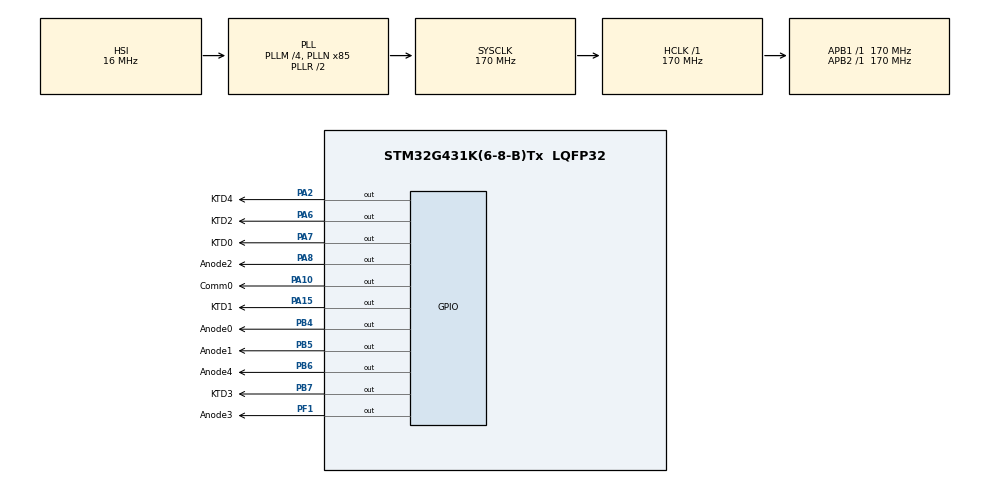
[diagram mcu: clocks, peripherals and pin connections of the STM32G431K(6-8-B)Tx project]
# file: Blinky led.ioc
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Mcu.Family=STM32G4
Mcu.Name=STM32G431K(6-8-B)Tx
Mcu.Package=LQFP32
NVIC.PriorityGroup=NVIC_PRIORITYGROUP_4
PA10.GPIO_Label=Comm0
PA10.Signal=GPIO_Output
PA13.GPIO_Label=T_SWDIO
PA13.Mode=Serial_Wire
PA13.Signal=SYS_JTMS-SWDIO
PA14.GPIO_Label=T_SWCLK
PA14.Mode=Serial_Wire
PA14.Signal=SYS_JTCK-SWCLK
PA15.GPIO_Label=KTD1
PA15.Signal=GPIO_Output
PA2.GPIO_Label=KTD4
PA2.Signal=GPIO_Output
PA6.GPIO_Label=KTD2
PA6.Signal=GPIO_Output
PA7.GPIO_Label=KTD0
PA7.PinState=GPIO_PIN_RESET
PA7.Signal=GPIO_Output
PA8.GPIO_Label=Anode2
PA8.Signal=GPIO_Output
PB3.GPIO_Label=T_SWO
PB3.Signal=SYS_JTDO-SWO
PB4.GPIO_Label=Anode0
PB4.PinState=GPIO_PIN_RESET
PB4.Signal=GPIO_Output
PB5.GPIO_Label=Anode1
PB5.Signal=GPIO_Output
PB6.GPIO_Label=Anode4
PB6.Signal=GPIO_Output
PB7.GPIO_Label=KTD3
PB7.Signal=GPIO_Output
PF1-OSC_OUT.GPIO_Label=Anode3
PF1-OSC_OUT.Signal=GPIO_Output
ProjectManager.HeapSize=0x200
ProjectManager.StackSize=0x400
ProjectManager.TargetToolchain=STM32CubeIDE
RCC.ADC12Freq_Value=170000000
RCC.AHBFreq_Value=170000000
RCC.APB1Freq_Value=170000000
RCC.APB1TimFreq_Value=170000000
RCC.APB2Freq_Value=170000000
RCC.APB2TimFreq_Value=170000000
RCC.CortexFreq_Value=170000000
RCC.EXTERNAL_CLOCK_VALUE=12288000
RCC.HCLKFreq_Value=170000000
RCC.HSE_VALUE=8000000
RCC.HSI48_VALUE=48000000
RCC.HSI_VALUE=16000000
RCC.LSE_VALUE=32768
RCC.PLLM=RCC_PLLM_DIV4
RCC.PLLN=85
RCC.SYSCLKFreq_VALUE=170000000
RCC.SYSCLKSource=RCC_SYSCLKSOURCE_PLLCLK
RCC.USBFreq_Value=170000000
RCC.VCOOutputFreq_Value=340000000
VP_SYS_VS_DBSignals.Mode=DisableDeadBatterySignals
board=NUCLEO-G431KB

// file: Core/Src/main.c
/* USER CODE BEGIN Header */
/**
  ******************************************************************************
  * @file           : main.c
  * @brief          : Main program body
  ******************************************************************************
  * @attention
  *
  * <h2><center>&copy; Copyright (c) 2021 STMicroelectronics.
  * All rights reserved.</center></h2>
  *
  * This software component is licensed by ST under BSD 3-Clause license,
  * the "License"; You may not use this file except in compliance with the
  * License. You may obtain a copy of the License at:
  *                        opensource.org/licenses/BSD-3-Clause
  *
  ******************************************************************************
  */
/* USER CODE END Header */
#include "main.h"

void SystemClock_Config(void);
static void MX_GPIO_Init(void);

int main(void)
{

  /* MCU Configuration--------------------------------------------------------*/

  /* Reset of all peripherals, Initializes the Flash interface and the Systick. */
  HAL_Init();

  /* USER CODE BEGIN Init */
int i=100;
  /* USER CODE END Init */

  /* Configure the system clock */
  SystemClock_Config();

  /* Initialize all configured peripherals */
  MX_GPIO_Init();

  /* Infinite loop */
  while (1)
  {
	 while (i>0 ,i-- )
	 {

	  /* Premier */
	  HAL_GPIO_WritePin (Anode0_GPIO_Port ,Anode0_Pin ,0);
	  HAL_GPIO_WritePin (Anode1_GPIO_Port ,Anode1_Pin ,1);
	  HAL_GPIO_WritePin (Anode2_GPIO_Port ,Anode2_Pin ,1);
	  HAL_GPIO_WritePin (Anode3_GPIO_Port ,Anode3_Pin ,1);
	  HAL_GPIO_WritePin (Anode4_GPIO_Port ,Anode4_Pin ,1);

	  HAL_GPIO_WritePin (KTD0_GPIO_Port ,KTD0_Pin ,1);
	  HAL_GPIO_WritePin (KTD1_GPIO_Port ,KTD1_Pin ,0);
	  HAL_GPIO_WritePin (KTD2_GPIO_Port ,KTD2_Pin ,0);
	  HAL_GPIO_WritePin (KTD3_GPIO_Port ,KTD3_Pin ,0);
	  HAL_GPIO_WritePin (KTD4_GPIO_Port ,KTD4_Pin ,0);
	  HAL_Delay(0);

	  /* Deuxième */

	  HAL_GPIO_WritePin (Anode0_GPIO_Port ,Anode0_Pin ,1);
	  HAL_GPIO_WritePin (Anode1_GPIO_Port ,Anode1_Pin ,0);
	  HAL_GPIO_WritePin (Anode2_GPIO_Port ,Anode2_Pin ,1);
	  HAL_GPIO_WritePin (Anode3_GPIO_Port ,Anode3_Pin ,1);
	  HAL_GPIO_WritePin (Anode4_GPIO_Port ,Anode4_Pin ,1);

	  HAL_GPIO_WritePin (KTD0_GPIO_Port ,KTD0_Pin ,0);
	  HAL_GPIO_WritePin (KTD1_GPIO_Port ,KTD1_Pin ,1);
	  HAL_GPIO_WritePin (KTD2_GPIO_Port ,KTD2_Pin ,0);
	  HAL_GPIO_WritePin (KTD3_GPIO_Port ,KTD3_Pin ,0);
	  HAL_GPIO_WritePin (KTD4_GPIO_Port ,KTD4_Pin ,0);
	  HAL_Delay(0);

	  /* Troisième */
	  HAL_GPIO_WritePin (Anode0_GPIO_Port ,Anode0_Pin ,1);
	  HAL_GPIO_WritePin (Anode1_GPIO_Port ,Anode1_Pin ,1);
	  HAL_GPIO_WritePin (Anode2_GPIO_Port ,Anode2_Pin ,0);
	  HAL_GPIO_WritePin (Anode3_GPIO_Port ,Anode3_Pin ,1);
	  HAL_GPIO_WritePin (Anode4_GPIO_Port ,Anode4_Pin ,1);

	  HAL_GPIO_WritePin (KTD0_GPIO_Port ,KTD0_Pin ,0);
	  HAL_GPIO_WritePin (KTD1_GPIO_Port ,KTD1_Pin ,0);
	  HAL_GPIO_WritePin (KTD2_GPIO_Port ,KTD2_Pin ,1);
	  HAL_GPIO_WritePin (KTD3_GPIO_Port ,KTD3_Pin ,0);
	  HAL_GPIO_WritePin (KTD4_GPIO_Port ,KTD4_Pin ,0);
	  HAL_Delay(0);

	  /* Quatrième */
	  HAL_GPIO_WritePin (Anode0_GPIO_Port ,Anode0_Pin ,1);
	  HAL_GPIO_WritePin (Anode1_GPIO_Port ,Anode1_Pin ,1);
	  HAL_GPIO_WritePin (Anode2_GPIO_Port ,Anode2_Pin ,1);
	  HAL_GPIO_WritePin (Anode3_GPIO_Port ,Anode3_Pin ,0);
	  HAL_GPIO_WritePin (Anode4_GPIO_Port ,Anode4_Pin ,1);

	  HAL_GPIO_WritePin (KTD0_GPIO_Port ,KTD0_Pin ,0);
	  HAL_GPIO_WritePin (KTD1_GPIO_Port ,KTD1_Pin ,0);
	  HAL_GPIO_WritePin (KTD2_GPIO_Port ,KTD2_Pin ,0);
	  HAL_GPIO_WritePin (KTD3_GPIO_Port ,KTD3_Pin ,1);
	  HAL_GPIO_WritePin (KTD4_GPIO_Port ,KTD4_Pin ,0);
	  HAL_Delay(0);

	  /* Cinquième */
	  HAL_GPIO_WritePin (Anode0_GPIO_Port ,Anode0_Pin ,1);
	  HAL_GPIO_WritePin (Anode1_GPIO_Port ,Anode1_Pin ,1);
	  HAL_GPIO_WritePin (Anode2_GPIO_Port ,Anode2_Pin ,1);
	  HAL_GPIO_WritePin (Anode3_GPIO_Port ,Anode3_Pin ,1);
	  HAL_GPIO_WritePin (Anode4_GPIO_Port ,Anode4_Pin ,0);

	  HAL_GPIO_WritePin (KTD0_GPIO_Port ,KTD0_Pin ,0);
	  HAL_GPIO_WritePin (KTD1_GPIO_Port ,KTD1_Pin ,0);
	  HAL_GPIO_WritePin (KTD2_GPIO_Port ,KTD2_Pin ,0);
	  HAL_GPIO_WritePin (KTD3_GPIO_Port ,KTD3_Pin ,0);
	  HAL_GPIO_WritePin (KTD4_GPIO_Port ,KTD4_Pin ,1);
	  HAL_Delay(0);

	  HAL_Delay(5);
	 }
	  HAL_GPIO_WritePin (Anode0_GPIO_Port ,Anode0_Pin ,1);
	  HAL_GPIO_WritePin (Anode1_GPIO_Port ,Anode1_Pin ,1);
	  HAL_GPIO_WritePin (Anode2_GPIO_Port ,Anode2_Pin ,1);
	  HAL_GPIO_WritePin (Anode3_GPIO_Port ,Anode3_Pin ,1);
	  HAL_GPIO_WritePin (Anode4_GPIO_Port ,Anode4_Pin ,1);

	  HAL_GPIO_WritePin (KTD0_GPIO_Port ,KTD0_Pin ,0);
	  HAL_GPIO_WritePin (KTD1_GPIO_Port ,KTD1_Pin ,0);
	  HAL_GPIO_WritePin (KTD2_GPIO_Port ,KTD2_Pin ,0);
	  HAL_GPIO_WritePin (KTD3_GPIO_Port ,KTD3_Pin ,0);
	  HAL_GPIO_WritePin (KTD4_GPIO_Port ,KTD4_Pin ,0);
	 i=100;
	HAL_Delay(500);
  }
}

void SystemClock_Config(void)
{
  RCC_OscInitTypeDef RCC_OscInitStruct = {0};
  RCC_ClkInitTypeDef RCC_ClkInitStruct = {0};

  /** Configure the main internal regulator output voltage
  */
  HAL_PWREx_ControlVoltageScaling(PWR_REGULATOR_VOLTAGE_SCALE1_BOOST);
  /** Initializes the RCC Oscillators according to the specified parameters
  * in the RCC_OscInitTypeDef structure.
  */
  RCC_OscInitStruct.OscillatorType = RCC_OSCILLATORTYPE_HSI;
  RCC_OscInitStruct.HSIState = RCC_HSI_ON;
  RCC_OscInitStruct.HSICalibrationValue = RCC_HSICALIBRATION_DEFAULT;
  RCC_OscInitStruct.PLL.PLLState = RCC_PLL_ON;
  RCC_OscInitStruct.PLL.PLLSource = RCC_PLLSOURCE_HSI;
  RCC_OscInitStruct.PLL.PLLM = RCC_PLLM_DIV4;
  RCC_OscInitStruct.PLL.PLLN = 85;
  RCC_OscInitStruct.PLL.PLLP = RCC_PLLP_DIV2;
  RCC_OscInitStruct.PLL.PLLQ = RCC_PLLQ_DIV2;
  RCC_OscInitStruct.PLL.PLLR = RCC_PLLR_DIV2;
  if (HAL_RCC_OscConfig(&RCC_OscInitStruct) != HAL_OK)
  {
    Error_Handler();
  }
  /** Initializes the CPU, AHB and APB buses clocks
  */
  RCC_ClkInitStruct.ClockType = RCC_CLOCKTYPE_HCLK|RCC_CLOCKTYPE_SYSCLK
                              |RCC_CLOCKTYPE_PCLK1|RCC_CLOCKTYPE_PCLK2;
  RCC_ClkInitStruct.SYSCLKSource = RCC_SYSCLKSOURCE_PLLCLK;
  RCC_ClkInitStruct.AHBCLKDivider = RCC_SYSCLK_DIV1;
  RCC_ClkInitStruct.APB1CLKDivider = RCC_HCLK_DIV1;
  RCC_ClkInitStruct.APB2CLKDivider = RCC_HCLK_DIV1;

  if (HAL_RCC_ClockConfig(&RCC_ClkInitStruct, FLASH_LATENCY_4) != HAL_OK)
  {
    Error_Handler();
  }
}

static void MX_GPIO_Init(void)
{
  GPIO_InitTypeDef GPIO_InitStruct = {0};

  /* GPIO Ports Clock Enable */
  __HAL_RCC_GPIOF_CLK_ENABLE();
  __HAL_RCC_GPIOA_CLK_ENABLE();
  __HAL_RCC_GPIOB_CLK_ENABLE();

  /*Configure GPIO pin Output Level */
  HAL_GPIO_WritePin(Anode3_GPIO_Port, Anode3_Pin, GPIO_PIN_RESET);

  /*Configure GPIO pin Output Level */
  HAL_GPIO_WritePin(GPIOA, KTD4_Pin|KTD2_Pin|KTD0_Pin|Anode2_Pin
                          |Comm0_Pin|KTD1_Pin, GPIO_PIN_RESET);

  /*Configure GPIO pin Output Level */
  HAL_GPIO_WritePin(GPIOB, Anode0_Pin|Anode1_Pin|Anode4_Pin|KTD3_Pin, GPIO_PIN_RESET);

  /*Configure GPIO pin : Anode3_Pin */
  GPIO_InitStruct.Pin = Anode3_Pin;
  GPIO_InitStruct.Mode = GPIO_MODE_OUTPUT_PP;
  GPIO_InitStruct.Pull = GPIO_NOPULL;
  GPIO_InitStruct.Speed = GPIO_SPEED_FREQ_LOW;
  HAL_GPIO_Init(Anode3_GPIO_Port, &GPIO_InitStruct);

  /*Configure GPIO pins : KTD4_Pin KTD2_Pin KTD0_Pin Anode2_Pin
                           Comm0_Pin KTD1_Pin */
  GPIO_InitStruct.Pin = KTD4_Pin|KTD2_Pin|KTD0_Pin|Anode2_Pin
                          |Comm0_Pin|KTD1_Pin;
  GPIO_InitStruct.Mode = GPIO_MODE_OUTPUT_PP;
  GPIO_InitStruct.Pull = GPIO_NOPULL;
  GPIO_InitStruct.Speed = GPIO_SPEED_FREQ_LOW;
  HAL_GPIO_Init(GPIOA, &GPIO_InitStruct);

  /*Configure GPIO pins : Anode0_Pin Anode1_Pin Anode4_Pin KTD3_Pin */
  GPIO_InitStruct.Pin = Anode0_Pin|Anode1_Pin|Anode4_Pin|KTD3_Pin;
  GPIO_InitStruct.Mode = GPIO_MODE_OUTPUT_PP;
  GPIO_InitStruct.Pull = GPIO_NOPULL;
  GPIO_InitStruct.Speed = GPIO_SPEED_FREQ_LOW;
  HAL_GPIO_Init(GPIOB, &GPIO_InitStruct);

}

void Error_Handler(void)
{
  __disable_irq();
  while (1)
  {
  }
}

/************************ (C) COPYRIGHT STMicroelectronics *****END OF FILE****/
